AUTOSAR XML (schema 4-0-3)
package /ComponentTypes
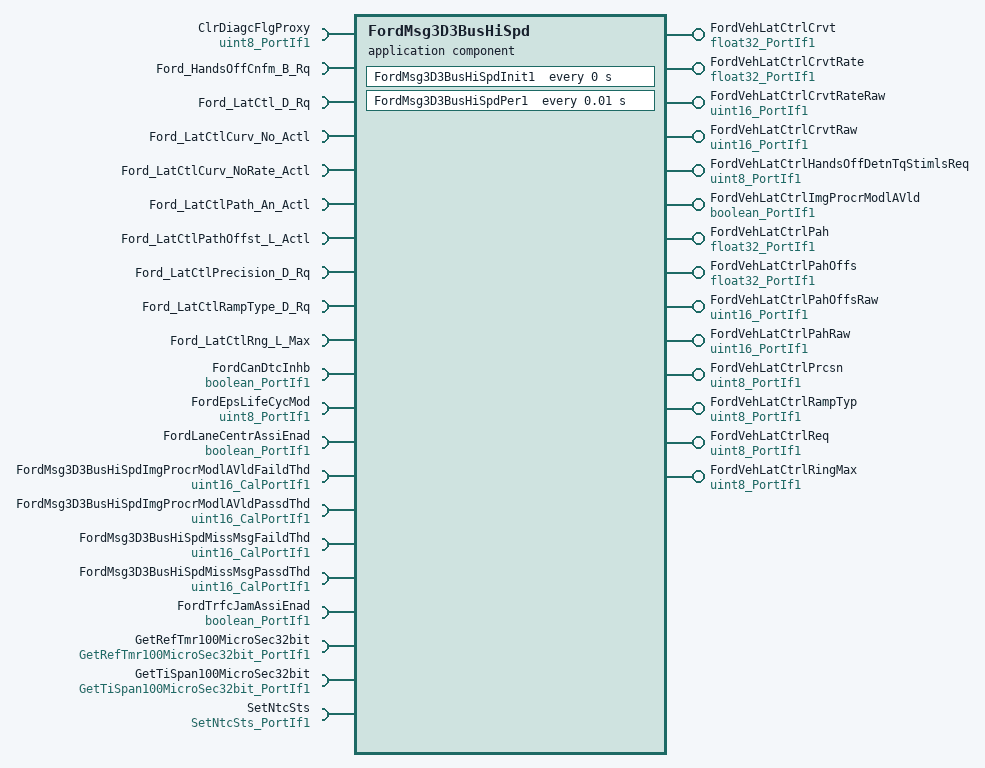
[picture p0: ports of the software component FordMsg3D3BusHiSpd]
  application sw component type FordMsg3D3BusHiSpd  # The purpose of the Ford Message 3D3 Bus High Speed function is to provide the Electric Power Steering system with signal values for the Traffic Jam Assist and Lane Center Assist functions from CAN. The Ford Message 3D3 function will perform the missing message as well as provide a validity flag for the signal values and received message.
    14 x provide port:
      FordVehLatCtrlCrvt: nonqueued-sender-com-spec{data-element=Val, init-value=0}, provided-interface=float32_PortIf1  # Processed value of Lateral Control Curvature
      FordVehLatCtrlCrvtRate: nonqueued-sender-com-spec{data-element=Val, init-value=0}, provided-interface=float32_PortIf1  # Processed value of Lateral Control Curvature Rate
      FordVehLatCtrlCrvtRateRaw: nonqueued-sender-com-spec{data-element=Val, init-value=4096}, provided-interface=uint16_PortIf1  # Processed value of Lateral Control Curvature Rate
      FordVehLatCtrlCrvtRaw: nonqueued-sender-com-spec{data-element=Val, init-value=1000}, provided-interface=uint16_PortIf1  # Processed value of Lateral Control Curvature
      FordVehLatCtrlHandsOffDetnTqStimlsReq: nonqueued-sender-com-spec{data-element=Val, init-value=0}, provided-interface=uint8_PortIf1  # Processed value of Lateral Control Hands Off Detection Torque Stimulus Request'
      FordVehLatCtrlImgProcrModlAVld: nonqueued-sender-com-spec{data-element=Logl, init-value=0}, provided-interface=boolean_PortIf1  # This output tells if the value for Ford Vehicle Lateral Control Image Processor Module A Valid is valid or not'
      FordVehLatCtrlPah: nonqueued-sender-com-spec{data-element=Val, init-value=0}, provided-interface=float32_PortIf1  # Processed value of Lateral Control Path
      FordVehLatCtrlPahOffs: nonqueued-sender-com-spec{data-element=Val, init-value=0}, provided-interface=float32_PortIf1  # Processed value of Lateral Control Path Offset
      FordVehLatCtrlPahOffsRaw: nonqueued-sender-com-spec{data-element=Val, init-value=512}, provided-interface=uint16_PortIf1  # Processed Value of Lateral Control Path Offset
      FordVehLatCtrlPahRaw: nonqueued-sender-com-spec{data-element=Val, init-value=1000}, provided-interface=uint16_PortIf1  # Processed value of Lateral Control Path
      FordVehLatCtrlPrcsn: nonqueued-sender-com-spec{data-element=Val, init-value=0}, provided-interface=uint8_PortIf1  # Processed value of Lateral Control Precision
      FordVehLatCtrlRampTyp: nonqueued-sender-com-spec{data-element=Val, init-value=0}, provided-interface=uint8_PortIf1  # Processed Value of Lateral Control Ramp Type
      FordVehLatCtrlReq: nonqueued-sender-com-spec{data-element=Val, init-value=0}, provided-interface=uint8_PortIf1  # Processed Value of Lateral Control Request
      FordVehLatCtrlRingMax: nonqueued-sender-com-spec{data-element=Val, init-value=0}, provided-interface=uint8_PortIf1  # Processed Value of Lateral Control Ring Max
    21 x require port:
      ClrDiagcFlgProxy: nonqueued-receiver-com-spec{data-element=Val, filter=data-filter-type=ALWAYS, init-value=0}, required-interface=uint8_PortIf1  # This Signal should be zero for the Diagnostics to function
      Ford_HandsOffCnfm_B_Rq: nonqueued-receiver-com-spec{data-element=Ford_HandsOffCnfm_B_Rq, filter=data-filter-type=ALWAYS, init-value=0}, required-interface=Ford_HandsOffCnfm_B_Rq  # It is a message signal which is received from CAN bus,which will be processed and used in EPS.Customer Data type : Ford_HandsOffCnfm_B_Rq,Sourcesignal range:[0,1], Cx0_Inactive,Cx1_Active
      Ford_LatCtl_D_Rq: nonqueued-receiver-com-spec{data-element=Ford_LatCtl_D_Rq, filter=data-filter-type=ALWAYS, init-value=0}, required-interface=Ford_LatCtl_D_Rq  # It is a message signal which is received from CAN bus,which will be processed and used in EPS.Customer Data type : Ford_LatCtl_D_Rq,Sourcesignal range:[0,7], Cx0_NoLateralControl,Cx1_ContinuousPathFollowingCx2_InterventionLeft,Cx3_InterventionRight,Cx4_NotUsed1,Cx5_NotUsed2Cx6_NotUsed3,Cx7_NotUsed4
      Ford_LatCtlCurv_No_Actl: nonqueued-receiver-com-spec{data-element=Ford_LatCtlCurv_No_Actl, filter=data-filter-type=ALWAYS, init-value=1000}, required-interface=Ford_LatCtlCurv_No_Actl  # It is a message signal which is received from CAN bus,which will be processed and used in EPS
      Ford_LatCtlCurv_NoRate_Actl: nonqueued-receiver-com-spec{data-element=Ford_LatCtlCurv_NoRate_Actl, filter=data-filter-type=ALWAYS, init-value=4096}, required-interface=Ford_LatCtlCurv_NoRate_Actl  # It is a message signal which is received from CAN bus,which will be processed and used in EPS
      Ford_LatCtlPath_An_Actl: nonqueued-receiver-com-spec{data-element=Ford_LatCtlPath_An_Actl, filter=data-filter-type=ALWAYS, init-value=1000}, required-interface=Ford_LatCtlPath_An_Actl  # It is a message signal which is received from CAN bus,which will be processed and used in EPS
      Ford_LatCtlPathOffst_L_Actl: nonqueued-receiver-com-spec{data-element=Ford_LatCtlPathOffst_L_Actl, filter=data-filter-type=ALWAYS, init-value=512}, required-interface=Ford_LatCtlPathOffst_L_Actl  # It is a message signal which is received from CAN bus,which will be processed and used in EPS
      Ford_LatCtlPrecision_D_Rq: nonqueued-receiver-com-spec{data-element=Ford_LatCtlPrecision_D_Rq, filter=data-filter-type=ALWAYS, init-value=0}, required-interface=Ford_LatCtlPrecision_D_Rq  # It is a message signal which is received from CAN bus,which will be pr'ocessed and used in EPS. Customer Data type : Ford_BrkTot_Tq_Act,Sourcesignal range:[0,3], Cx0_Comfortable,Cx1_Precise,Cx3_NotUsed2,Cx3_NotUsed2'
      Ford_LatCtlRampType_D_Rq: nonqueued-receiver-com-spec{data-element=Ford_LatCtlRampType_D_Rq, filter=data-filter-type=ALWAYS, init-value=0}, required-interface=Ford_LatCtlRampType_D_Rq  # It is a message signal which is received from CAN bus,which will be processed and used in EPS.Customer Data type : Ford_LatCtlRampType_D_Rq,Sourcesignal range:[0,3], Cx0_Slow,Cx1_Medium,Cx2_Fast,Cx3_Immediately
      Ford_LatCtlRng_L_Max: nonqueued-receiver-com-spec{data-element=Ford_LatCtlRng_L_Max, filter=data-filter-type=ALWAYS, init-value=0}, required-interface=Ford_LatCtlRng_L_Max  # It is a message signal which is received from CAN bus,which will be processed and used in EPS
      FordCanDtcInhb: nonqueued-receiver-com-spec{data-element=Logl, filter=data-filter-type=ALWAYS, init-value=1}, required-interface=boolean_PortIf1  # This signal should be set to 0 to enable the diagnostics.Data Type: Boolean with Minvalue “False”(0), Init value “True”(1) and Max value “True”(1)
      FordEpsLifeCycMod: nonqueued-receiver-com-spec{data-element=Val, filter=data-filter-type=ALWAYS, init-value=0}, required-interface=uint8_PortIf1  # This signal is used to decide threshold value to FAIL the NTC
      FordLaneCentrAssiEnad: nonqueued-receiver-com-spec{data-element=Logl, filter=data-filter-type=ALWAYS, init-value=0}, required-interface=boolean_PortIf1  # This signal should be set to 1 in order to Test Diagnostic NTC. Data Type: Boolean with Minvalue “False”(0), Init value “False”(0) and Max value “True”(1)
      FordMsg3D3BusHiSpdImgProcrModlAVldFaildThd: parameter-require-com-spec{init-value=1000, parameter=Val}, required-interface=uint16_CalPortIf1  # Threshold to set the FordVehLatCtrlImgProcrModlAVld to false
      FordMsg3D3BusHiSpdImgProcrModlAVldPassdThd: parameter-require-com-spec{init-value=5000, parameter=Val}, required-interface=uint16_CalPortIf1  # Threshold to set the FordVehLatCtrlImgProcrModlAVld to true
      FordMsg3D3BusHiSpdMissMsgFaildThd: parameter-require-com-spec{init-value=1000, parameter=Val}, required-interface=uint16_CalPortIf1  # Threshold to set FordMsg3D3MissMsg NTC
      FordMsg3D3BusHiSpdMissMsgPassdThd: parameter-require-com-spec{init-value=0, parameter=Val}, required-interface=uint16_CalPortIf1  # Threshold to Reset FordMsg3D3MissMsg NTC
      FordTrfcJamAssiEnad: nonqueued-receiver-com-spec{data-element=Logl, filter=data-filter-type=ALWAYS, init-value=0}, required-interface=boolean_PortIf1  # This signal should be set to 1 in order to Test Diagnostic NTC. Data Type: Boolean with Minvalue “False”(0), Init value “False”(0) and Max value “True”(1)
      GetRefTmr100MicroSec32bit: client-com-spec=Oper, required-interface=GetRefTmr100MicroSec32bit_PortIf1  # It captures simulation time from the SimnTi value obtained at root layer of model and gives the RefTmr.
      GetTiSpan100MicroSec32bit: client-com-spec=Oper, required-interface=GetTiSpan100MicroSec32bit_PortIf1  # It Captures simulation time fromSimnTi value, handles counter wrapping, and subtracts RefTmr,provides the TiSpan
      SetNtcSts: client-com-spec=Oper, required-interface=SetNtcSts_PortIf1  # Set the NTC status
    behavior FordMsg3D3BusHiSpd_InternalBehavior
      ar-typed-per-instance-memorys:
        21 x data, all with sw-calibration-access=READ-ONLY:
          ClrDiagcFlgProxyPrev: type=uint8  # Clear Diagc Flag Proxy
          FirstTranVldFlg: type=boolean  # This flag is used to indicate the reception of first message
          FordVehLatCtrlCrvtPrev: type=float32  # It is used to hold the previous value of FordVehLatCtrlCrvt
          FordVehLatCtrlCrvtRatePrev: type=float32  # It is used to hold the previous value of FordVehLatCtrlCrvtRate
          FordVehLatCtrlCrvtRateRawPrev: type=uint16  # It is used to hold the previous value of FordVehLatCtrlCrvtRateRaw
          FordVehLatCtrlCrvtRawPrev: type=uint16  # It is used to hold the previous value of FordVehLatCtrlCrvtRaw
          FordVehLatCtrlHandsOffDetnTqStimlsReqPrev: type=Ford_HandsOffCnfm_B_Rq  # It is used to hold the previous value of FordVehLatCtrlHandsOffDetnTqStmlsReq
          FordVehLatCtrlImgProcrModlAVldPrev: type=boolean  # It is used to hold the previous value of FordVehLatCtrlImgProcrModlAVld
          FordVehLatCtrlPahOffsPrev: type=float32  # It is used to hold the previous value of FordVehLatCtrlPahOffs
          FordVehLatCtrlPahOffsRawPrev: type=uint16  # It is used to hold the previous value of FordVehLatCtrlPahOffsRaw
          FordVehLatCtrlPahPrev: type=float32  # It is used to hold the previous value of FordVehLatCtrlPah
          FordVehLatCtrlPahRawPrev: type=uint16  # It is used to hold the previous value of FordVehLatCtrlPahRaw
          FordVehLatCtrlPrcsnPrev: type=Ford_LatCtlPrecision_D_Rq  # It is used to hold the previous value of FordVehLatCtrlPrcsn
          FordVehLatCtrlRampTypPrev: type=Ford_LatCtlRampType_D_Rq  # It is used to hold the previous value of FordVehLatCtrlRampTyp
          FordVehLatCtrlReqPrev: type=Ford_LatCtl_D_Rq  # It is used to hold the previous value of FordVehLatCtrlReq
          FordVehLatCtrlRingMaxPrev: type=uint8  # It is used to hold the previous value of FordVehLatCtrlRingMax
          FordVehMsg3D3Miss: type=boolean  # Used to hold value of Ford Vehicle message 3D3 miss
          ImgProcrModlAVldFaildRefTi: type=uint32  # Timer for Valid Failed Reference Time will increment or reset based on the conditions
          ImgProcrModlAVldPassdRefTi: type=uint32  # Timer for Valid Passed Reference Time will increment or reset based on the conditions
          MissMsgFaildRefTi: type=uint32  # Timer for misisng message will increment or reset based on the conditi'ons'
          MissMsgPassdRefTi: type=uint32  # Timer for misisng message will increment or reset based on the conditions
      timing event FordMsg3D3BusHiSpd_InitEvent: start-on-event=FordMsg3D3BusHiSpdInit1, period=0
      timing event TMT_FordMsg3D3BusHiSpdPer1: start-on-event=FordMsg3D3BusHiSpdPer1, period=0.01
      port-api-options:
        enable-take-address=false, indirect-api=false, port=ClrDiagcFlgProxy
        enable-take-address=false, indirect-api=false, port=Ford_LatCtlPath_An_Actl
        enable-take-address=false, indirect-api=false, port=Ford_LatCtlPathOffst_L_Actl
        enable-take-address=false, indirect-api=false, port=FordCanDtcInhb
        enable-take-address=false, indirect-api=false, port=FordTrfcJamAssiEnad
        enable-take-address=false, indirect-api=false, port=FordVehLatCtrlCrvt
        enable-take-address=false, indirect-api=false, port=FordVehLatCtrlCrvtRate
        enable-take-address=false, indirect-api=false, port=FordVehLatCtrlHandsOffDetnTqStimlsReq
        enable-take-address=false, indirect-api=false, port=FordVehLatCtrlImgProcrModlAVld
        enable-take-address=false, indirect-api=false, port=FordVehLatCtrlPah
        enable-take-address=false, indirect-api=false, port=FordVehLatCtrlReq
        enable-take-address=false, indirect-api=false, port=FordVehLatCtrlRingMax
      runnable FordMsg3D3BusHiSpdInit1  # Initialization Runnable
        sync call SC_GetRefTmr100MicroSec32bit_Oper: operation=GetRefTmr100MicroSec32bit.Oper, timeout=0
      runnable FordMsg3D3BusHiSpdPer1  # Periodic Runnable at 10 milli-seconds
        data-receive-point-by-arguments:
          19 x access:
            REC_ClrDiagcFlgProxy_Val: accessed-variable=ClrDiagcFlgProxy.Val
            REC_Ford_HandsOffCnfm_B_Rq1_Ford_HandsOffCnfm_B_Rq: accessed-variable=Ford_HandsOffCnfm_B_Rq.Ford_HandsOffCnfm_B_Rq
            REC_Ford_LatCtl_D_Rq1_Ford_LatCtl_D_Rq: accessed-variable=Ford_LatCtl_D_Rq.Ford_LatCtl_D_Rq
            REC_Ford_LatCtlCurv_No_Actl_Ford_LatCtlCurv_No_Actl: accessed-variable=Ford_LatCtlCurv_No_Actl.Ford_LatCtlCurv_No_Actl
            REC_Ford_LatCtlCurv_No_Actl_Val: accessed-variable=Ford_LatCtlCurv_No_Actl.Val
            REC_Ford_LatCtlCurv_NoRate_Actl_Ford_LatCtlCurv_NoRate_Actl: accessed-variable=Ford_LatCtlCurv_NoRate_Actl.Ford_LatCtlCurv_NoRate_Actl
            REC_Ford_LatCtlCurv_NoRate_Actl_Val: accessed-variable=Ford_LatCtlCurv_NoRate_Actl.Val
            REC_Ford_LatCtlPath_An_Actl_Ford_LatCtlPath_An_Actl: accessed-variable=Ford_LatCtlPath_An_Actl.Ford_LatCtlPath_An_Actl
            REC_Ford_LatCtlPath_An_Actl_Val: accessed-variable=Ford_LatCtlPath_An_Actl.Val
            REC_Ford_LatCtlPathOffst_L_Actl_Ford_LatCtlPathOffst_L_Actl: accessed-variable=Ford_LatCtlPathOffst_L_Actl.Ford_LatCtlPathOffst_L_Actl
            REC_Ford_LatCtlPathOffst_L_Actl_Val: accessed-variable=Ford_LatCtlPathOffst_L_Actl.Val
            REC_Ford_LatCtlPrecision_D_Rq_Ford_LatCtlPrecision_D_Rq: accessed-variable=Ford_LatCtlPrecision_D_Rq.Ford_LatCtlPrecision_D_Rq
            REC_Ford_LatCtlRampType_D_Rq1_Ford_LatCtlRampType_D_Rq: accessed-variable=Ford_LatCtlRampType_D_Rq.Ford_LatCtlRampType_D_Rq
            REC_Ford_LatCtlRng_L_Max_Ford_LatCtlRng_L_Max: accessed-variable=Ford_LatCtlRng_L_Max.Ford_LatCtlRng_L_Max
            REC_Ford_LatCtlRng_L_Max_Val: accessed-variable=Ford_LatCtlRng_L_Max.Val
            REC_FordCanDtcInhb_Logl: accessed-variable=FordCanDtcInhb.Logl
            REC_FordEpsLifeCycMod_Val: accessed-variable=FordEpsLifeCycMod.Val
            REC_FordLaneCentrAssiEnad_Logl: accessed-variable=FordLaneCentrAssiEnad.Logl
            REC_FordTrfcJamAssiEnad_Logl: accessed-variable=FordTrfcJamAssiEnad.Logl
        data-send-points:
          18 x access:
            SEND_FordVehLatCtrlCrvt_Val: accessed-variable=FordVehLatCtrlCrvt.Val
            SEND_FordVehLatCtrlCrvtRate_Val: accessed-variable=FordVehLatCtrlCrvtRate.Val
            SEND_FordVehLatCtrlCrvtRateRaw_Val: accessed-variable=FordVehLatCtrlCrvtRateRaw.Val
            SEND_FordVehLatCtrlCrvtRaw_Val: accessed-variable=FordVehLatCtrlCrvtRaw.Val
            SEND_FordVehLatCtrlHandsOffDetnTqStimlsReq_Ford_HandsOffCnfm_B_Rq: accessed-variable=FordVehLatCtrlHandsOffDetnTqStimlsReq.Ford_HandsOffCnfm_B_Rq
            SEND_FordVehLatCtrlHandsOffDetnTqStimlsReq_Val: accessed-variable=FordVehLatCtrlHandsOffDetnTqStimlsReq.Val
            SEND_FordVehLatCtrlImgProcrModlAVld_Logl: accessed-variable=FordVehLatCtrlImgProcrModlAVld.Logl
            SEND_FordVehLatCtrlPah_Val: accessed-variable=FordVehLatCtrlPah.Val
            SEND_FordVehLatCtrlPahOffs_Val: accessed-variable=FordVehLatCtrlPahOffs.Val
            SEND_FordVehLatCtrlPahOffsRaw_Val: accessed-variable=FordVehLatCtrlPahOffsRaw.Val
            SEND_FordVehLatCtrlPahRaw_Val: accessed-variable=FordVehLatCtrlPahRaw.Val
            SEND_FordVehLatCtrlPrcsn_Ford_LatCtlPrecision_D_Rq: accessed-variable=FordVehLatCtrlPrcsn.Ford_LatCtlPrecision_D_Rq
            SEND_FordVehLatCtrlPrcsn_Val: accessed-variable=FordVehLatCtrlPrcsn.Val
            SEND_FordVehLatCtrlRampTyp_Ford_LatCtlRampType_D_Rq: accessed-variable=FordVehLatCtrlRampTyp.Ford_LatCtlRampType_D_Rq
            SEND_FordVehLatCtrlRampTyp_Val: accessed-variable=FordVehLatCtrlRampTyp.Val
            SEND_FordVehLatCtrlReq_Ford_LatCtl_D_Rq: accessed-variable=FordVehLatCtrlReq.Ford_LatCtl_D_Rq
            SEND_FordVehLatCtrlReq_Val: accessed-variable=FordVehLatCtrlReq.Val
            SEND_FordVehLatCtrlRingMax_Val: accessed-variable=FordVehLatCtrlRingMax.Val
        sync call SC_GetRefTmr100MicroSec32bit_Oper: operation=GetRefTmr100MicroSec32bit.Oper, timeout=0
        sync call SC_GetTiSpan100MicroSec32bit_Oper: operation=GetTiSpan100MicroSec32bit.Oper, timeout=0
        sync call SC_SetNtcSts_Oper: operation=SetNtcSts.Oper, timeout=0
  swc implementation FordMsg3D3BusHiSpd_Implementation: behavior=FordMsg3D3BusHiSpd_InternalBehavior
    code-descriptors:
      code Default: artifact-descriptors=autosar-engineering-object={short-label=Default, category=SWSRC}
